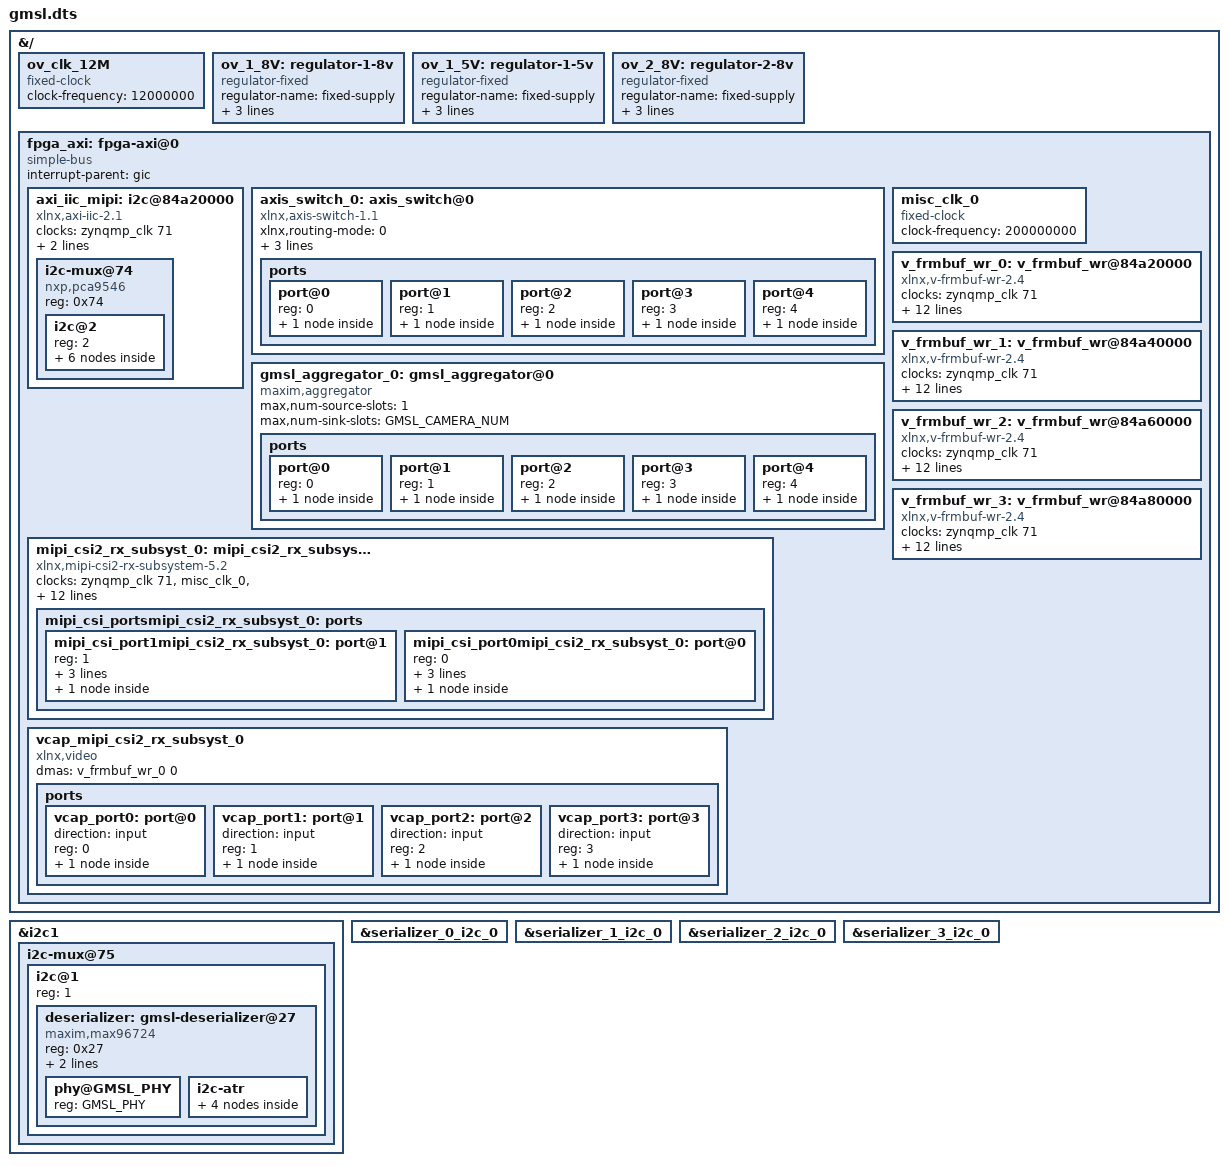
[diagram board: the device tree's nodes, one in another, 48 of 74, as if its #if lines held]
// SPDX-License-Identifier: GPL-2.0
/*
 */

#include <dt-bindings/gpio/gpio.h>

/dts-v1/;
/plugin/;

//#define BRD_KRIA
#define BRD_ZCU

#define GMSL_CAM_ISX021
//#define GMSL_CAM_OVX03A

//GMSL defines
#define GMSL_CAMERA_NUM	1
#define GMSL_PHY	0x1

#if (GMSL_CAMERA_NUM >= 1)
#define GMSL_CAMERA_0
#endif
#if (GMSL_CAMERA_NUM >= 2)
#define GMSL_CAMERA_1
#endif
#if (GMSL_CAMERA_NUM >= 3)
#define GMSL_CAMERA_2
#endif
#if (GMSL_CAMERA_NUM >= 4)
#define GMSL_CAMERA_3
#endif

#define GMSL_SER_0_HEX_ADDR	0x41
#define GMSL_SER_1_HEX_ADDR	0x42
#define GMSL_SER_2_HEX_ADDR	0x43
#define GMSL_SER_3_HEX_ADDR	0x44

#define GMSL_CAM_0_HEX_ADDR	0x1b
#define GMSL_CAM_1_HEX_ADDR	0x1c
#define GMSL_CAM_2_HEX_ADDR	0x1d
#define GMSL_CAM_3_HEX_ADDR	0x1e

#define _CONCAT(a, b) a ## b
#define CONCAT(a, b) _CONCAT(a, b)

#define _STRINGIFY(a) # a
#define STRINGIFY(a) _STRINGIFY(a)

&{/} {
	ov_clk_12M: ov_clk_12M {
		compatible = "fixed-clock";
		#clock-cells = <0>;
		clock-frequency = <12000000>;
	};

	ov_1_8V: regulator-1-8v {
		compatible = "regulator-fixed";
		regulator-name = "fixed-supply";
		regulator-min-microvolt = <1800000>;
		regulator-max-microvolt = <1800000>;
		regulator-always-on;
	};

	ov_1_5V: regulator-1-5v {
		compatible = "regulator-fixed";
		regulator-name = "fixed-supply";
		regulator-min-microvolt = <1500000>;
		regulator-max-microvolt = <1500000>;
		regulator-always-on;
	};

	ov_2_8V: regulator-2-8v {
		compatible = "regulator-fixed";
		regulator-name = "fixed-supply";
		regulator-min-microvolt = <2800000>;
		regulator-max-microvolt = <2800000>;
		regulator-always-on;
	};

	fpga_axi: fpga-axi@0 {
		interrupt-parent = <&gic>;
		#address-cells = <1>;
		#size-cells = <1>;
		compatible = "simple-bus";
		ranges = <0 0 0 0xffffffff>;
#ifdef BRD_KRIA
		axi_iic_mipi: i2c@84a20000 {
			#address-cells = <1>;
			#size-cells = <0>;
			clock-names = "s_axi_aclk";
			clocks = <&zynqmp_clk 71>;
			compatible = "xlnx,axi-iic-2.1", "xlnx,xps-iic-2.00.a";
			reg = <0x84a20000 0x1000>;
			interrupts = <0 108 4>;
		};
#endif

		axis_switch_0: axis_switch@0 {
			compatible = "xlnx,axis-switch-1.1";
			xlnx,routing-mode = <0>;
			xlnx,num-si-slots = <1>;
			xlnx,num-mi-slots = <GMSL_CAMERA_NUM>;
			clock-names = "aclk";
			clocks = <&zynqmp_clk 71>;
			ports {
				#address-cells = <1>;
				#size-cells = <0>;
				port@0 {
					reg = <0>;
					switch_in0: endpoint {
						remote-endpoint = <&mipi_csirx_outmipi_csi2_rx_subsyst_0>;
					};
				};
#if defined (GMSL_CAMERA_0)
				port@1 {
					reg = <1>;
					switch_out0: endpoint {
						remote-endpoint = <&vcap_portswitch0>;
					};
				};
#endif
#if defined (GMSL_CAMERA_1)
				port@2 {
					reg = <2>;
					switch_out1: endpoint {
						remote-endpoint = <&vcap_portswitch1>;
					};
				};
#endif
#if defined (GMSL_CAMERA_2)
				port@3 {
					reg = <3>;
					switch_out2: endpoint {
						remote-endpoint = <&vcap_portswitch2>;
					};
				};
#endif
#if defined (GMSL_CAMERA_3)
				port@4 {
					reg = <4>;
					switch_out3: endpoint {
						remote-endpoint = <&vcap_portswitch3>;
					};
				};
#endif
			};
		};

		gmsl_aggregator_0: gmsl_aggregator@0 {
			compatible = "maxim,aggregator";
			max,num-source-slots = <1>;
			max,num-sink-slots = <GMSL_CAMERA_NUM>;
			ports {
				#address-cells = <1>;
				#size-cells = <0>;
				port@0 {
					reg = <0>;
					aggr_out0: endpoint {
						remote-endpoint = <&mipi_csi_inmipi_csi2_rx_subsyst_0>;
					};
				};
#if defined (GMSL_CAMERA_0)
				port@1 {
					reg = <1>;
					csi_in0: endpoint {
						remote-endpoint = <&deser_out0>;
#ifdef BRD_ZCU
						data-lanes = <1 2 3 4>;
#else
						data-lanes = <1 2>;
#endif
					};
				};
#endif
#if defined (GMSL_CAMERA_1)
				port@2 {
					reg = <2>;
					csi_in1: endpoint {
						remote-endpoint = <&deser_out1>;
#ifdef BRD_ZCU
						data-lanes = <1 2 3 4>;
#else
						data-lanes = <1 2>;
#endif
					};
				};
#endif
#if defined (GMSL_CAMERA_2)
				port@3 {
					reg = <3>;
					csi_in2: endpoint {
						remote-endpoint = <&deser_out2>;
#ifdef BRD_ZCU
						data-lanes = <1 2 3 4>;
#else
						data-lanes = <1 2>;
#endif
					};
				};
#endif
#if defined (GMSL_CAMERA_3)
				port@4 {
					reg = <4>;
					csi_in3: endpoint {
						remote-endpoint = <&deser_out3>;
#ifdef BRD_ZCU
						data-lanes = <1 2 3 4>;
#else
						data-lanes = <1 2>;
#endif
					};
				};
#endif
			};
		};

		mipi_csi2_rx_subsyst_0: mipi_csi2_rx_subsystem@84a00000 {
			clock-names = "lite_aclk", "dphy_clk_200M", "video_aclk";
			clocks = <&zynqmp_clk 71>, <&misc_clk_0>, <&zynqmp_clk 71>;
			compatible = "xlnx,mipi-csi2-rx-subsystem-5.2", "xlnx,mipi-csi2-rx-subsystem-5.0";
			interrupt-names = "csirxss_csi_irq";
			interrupt-parent = <&gic>;
			interrupts = <0 109 4>;
			xlnx,csi-pxl-format = <0x1E>;
#ifdef BRD_ZCU
			video-reset-gpios = <&gpio 99 GPIO_ACTIVE_LOW>;
#else
			video-reset-gpios = <&gpio 79 GPIO_ACTIVE_LOW>;
#endif
			reg = <0x84a00000 0x2000>;
			xlnx,axis-tdata-width = <32>;
			xlnx,dphy-present ;
			xlnx,max-lanes = <4>;
			xlnx,ppc = <2>;
			xlnx,vc = <4>;
			xlnx,vfb ;
			mipi_csi_portsmipi_csi2_rx_subsyst_0: ports {
				#address-cells = <1>;
				#size-cells = <0>;
				mipi_csi_port1mipi_csi2_rx_subsyst_0: port@1 {
					/* Fill cfa-pattern=rggb for raw data types, other fields video-format and video-width user needs to fill */
					reg = <1>;
					xlnx,cfa-pattern = "rggb";
					xlnx,video-format = <0>;
					xlnx,video-width = <8>;
					mipi_csirx_outmipi_csi2_rx_subsyst_0: endpoint {
						remote-endpoint = <&switch_in0>;
					};
				};
				mipi_csi_port0mipi_csi2_rx_subsyst_0: port@0 {
					/* Fill cfa-pattern=rggb for raw data types, other fields video-format,video-width user needs to fill */
					/* User need to add something like remote-endpoint=<&out> under the node csiss_in:endpoint */
					reg = <0>;
					xlnx,cfa-pattern = "rggb";
					xlnx,video-format = <0>;
					xlnx,video-width = <8>;
					mipi_csi_inmipi_csi2_rx_subsyst_0: endpoint {
						remote-endpoint = <&aggr_out0>;
#ifdef BRD_ZCU
						data-lanes = <1 2 3 4>;
#else
						data-lanes = <1 2>;
#endif
					};
				};
			};
		};

		misc_clk_0: misc_clk_0 {
			#clock-cells = <0>;
			clock-frequency = <200000000>;
			compatible = "fixed-clock";
		};

#if defined (GMSL_CAMERA_0)
		v_frmbuf_wr_0: v_frmbuf_wr@84a20000 {
			#dma-cells = <1>;
			clock-names = "ap_clk";
			clocks = <&zynqmp_clk 71>;
			compatible = "xlnx,v-frmbuf-wr-2.4", "xlnx,axi-frmbuf-wr-v2.2";
			interrupt-names = "interrupt";
			interrupt-parent = <&gic>;
			interrupts = <0 107 4>;
#ifdef BRD_ZCU
			reset-gpios = <&gpio 100 GPIO_ACTIVE_LOW>;
#else
			reset-gpios = <&gpio 80 GPIO_ACTIVE_LOW>;
#endif
			reg = <0x84a20000 0x10000>;
			xlnx,dma-addr-width = <32>;
			xlnx,max-height = <2160>;
			xlnx,max-width = <3840>;
			xlnx,pixels-per-clock = <2>;
			xlnx,s-axi-ctrl-addr-width = <0x7>;
			xlnx,s-axi-ctrl-data-width = <0x20>;
			xlnx,vid-formats = "bgr888", "uyvy", "yuyv", "nv16";
			xlnx,video-width = <8>;
		};
#endif
#if defined (GMSL_CAMERA_1)
		v_frmbuf_wr_1: v_frmbuf_wr@84a40000 {
			#dma-cells = <1>;
			clock-names = "ap_clk";
			clocks = <&zynqmp_clk 71>;
			compatible = "xlnx,v-frmbuf-wr-2.4", "xlnx,axi-frmbuf-wr-v2.2";
			interrupt-names = "interrupt";
			interrupt-parent = <&gic>;
			interrupts = <0 106 4>;
#ifdef BRD_ZCU
			reset-gpios = <&gpio 101 GPIO_ACTIVE_LOW>;
#else
			reset-gpios = <&gpio 81 GPIO_ACTIVE_LOW>;
#endif
			reg = <0x84a40000 0x10000>;
			xlnx,dma-addr-width = <32>;
			xlnx,max-height = <2160>;
			xlnx,max-width = <3840>;
			xlnx,pixels-per-clock = <2>;
			xlnx,s-axi-ctrl-addr-width = <0x7>;
			xlnx,s-axi-ctrl-data-width = <0x20>;
			xlnx,vid-formats = "bgr888", "uyvy", "yuyv", "nv16";
			xlnx,video-width = <8>;
		};
#endif
#if defined (GMSL_CAMERA_2)
		v_frmbuf_wr_2: v_frmbuf_wr@84a60000 {
			#dma-cells = <1>;
			clock-names = "ap_clk";
			clocks = <&zynqmp_clk 71>;
			compatible = "xlnx,v-frmbuf-wr-2.4", "xlnx,axi-frmbuf-wr-v2.2";
			interrupt-names = "interrupt";
			interrupt-parent = <&gic>;
			interrupts = <0 105 4>;
#ifdef BRD_ZCU
			reset-gpios = <&gpio 102 GPIO_ACTIVE_LOW>;
#else
			reset-gpios = <&gpio 82 GPIO_ACTIVE_LOW>;
#endif
			reg = <0x84a60000 0x10000>;
			xlnx,dma-addr-width = <32>;
			xlnx,max-height = <2160>;
			xlnx,max-width = <3840>;
			xlnx,pixels-per-clock = <2>;
			xlnx,s-axi-ctrl-addr-width = <0x7>;
			xlnx,s-axi-ctrl-data-width = <0x20>;
			xlnx,vid-formats = "bgr888", "uyvy", "yuyv", "nv16";
			xlnx,video-width = <8>;
		};
#endif
#if defined (GMSL_CAMERA_3)
		v_frmbuf_wr_3: v_frmbuf_wr@84a80000 {
			#dma-cells = <1>;
			clock-names = "ap_clk";
			clocks = <&zynqmp_clk 71>;
			compatible = "xlnx,v-frmbuf-wr-2.4", "xlnx,axi-frmbuf-wr-v2.2";
			interrupt-names = "interrupt";
			interrupt-parent = <&gic>;
			interrupts = <0 104 4>;
#ifdef BRD_ZCU
			reset-gpios = <&gpio 103 GPIO_ACTIVE_LOW>;
#else
			reset-gpios = <&gpio 83 GPIO_ACTIVE_LOW>;
#endif
			reg = <0x84a80000 0x10000>;
			xlnx,dma-addr-width = <32>;
			xlnx,max-height = <2160>;
			xlnx,max-width = <3840>;
			xlnx,pixels-per-clock = <2>;
			xlnx,s-axi-ctrl-addr-width = <0x7>;
			xlnx,s-axi-ctrl-data-width = <0x20>;
			xlnx,vid-formats = "bgr888", "uyvy", "yuyv", "nv16";
			xlnx,video-width = <8>;
		};
#endif
		vcap_mipi_csi2_rx_subsyst_0 {
			compatible = "xlnx,video";
			dma-names = "port0", "port1", "port2", "port3";
#if (GMSL_CAMERA_NUM == 1)
			dmas = <&v_frmbuf_wr_0 0>;
#elif (GMSL_CAMERA_NUM == 2)
			dmas = <&v_frmbuf_wr_0 0>, <&v_frmbuf_wr_1 0>;
#elif (GMSL_CAMERA_NUM == 3)
			dmas = <&v_frmbuf_wr_0 0>, <&v_frmbuf_wr_1 0>, <&v_frmbuf_wr_2 0>;
#elif (GMSL_CAMERA_NUM == 4)
			dmas = <&v_frmbuf_wr_0 0>, <&v_frmbuf_wr_1 0>, <&v_frmbuf_wr_2 0>, <&v_frmbuf_wr_3 0>;
#else
	#error "GMSL_CAMERA_NUM has wrong value"
#endif
			ports {
				#address-cells = <1>;
				#size-cells = <0>;
#if defined (GMSL_CAMERA_0)
				vcap_port0: port@0 {
					direction = "input";
					reg = <0>;
					vcap_portswitch0: endpoint {
						remote-endpoint = <&switch_out0>;
					};
				};
#endif
#if defined (GMSL_CAMERA_1)
				vcap_port1: port@1 {
					direction = "input";
					reg = <1>;
					vcap_portswitch1: endpoint {
						remote-endpoint = <&switch_out1>;
					};
				};
#endif
#if defined (GMSL_CAMERA_2)
				vcap_port2: port@2 {
					direction = "input";
					reg = <2>;
					vcap_portswitch2: endpoint {
						remote-endpoint = <&switch_out2>;
					};
				};
#endif
#if defined (GMSL_CAMERA_3)
				vcap_port3: port@3 {
					direction = "input";
					reg = <3>;
					vcap_portswitch3: endpoint {
						remote-endpoint = <&switch_out3>;
					};
				};
#endif
			};
		};
	};

};

#ifdef BRD_ZCU
&i2c1{
	#address-cells = <1>;
	#size-cells = <0>;
	i2c-mux@75 {
		#address-cells = <1>;
		#size-cells = <0>;
		i2c@1 {
			#address-cells = <1>;
			#size-cells = <0>;
			reg = <1>;
			deserializer: gmsl-deserializer@27 {
				#address-cells = <1>;
				#size-cells = <0>;
				compatible = "maxim,max96724";
				reg = <0x27>;
			};
		};
	};
};
#endif

#ifdef BRD_KRIA
&axi_iic_mipi { 
	i2c-mux@74 {
		compatible = "nxp,pca9546"; /* u18 */
		#address-cells = <1>;
		#size-cells = <0>;
		reg = <0x74>;
		i2c@2 {
			#address-cells = <1>;
			#size-cells = <0>;
			reg = <2>;
			deserializer: gmsl-deserializer@27 {
				#address-cells = <1>;
				#size-cells = <0>;
				compatible = "maxim,max96724";
				reg = <0x27>;

				gpio-controller;
				#gpio-cells = <2>;

				pinctrl-0 = <&mfp0_fsync0 &mfp1_fsync1 &mfp2_fsync2 &mfp3_fsync3>;
				pinctrl-names = "default";
				pins {
					mfp0_fsync0: mfp0_fsync0 {
						pins = "mfp0";
						function = "gpio";
						bias-pull-up;
						input-enable;
						maxim,jitter-compensation = <1>;
						maxim,gmsl-tx-a = <1>;
						maxim,gmsl-tx-id-a = <0>;
						maxim,gmsl-tx-b = <1>;
						maxim,gmsl-tx-id-b = <0>;
						maxim,gmsl-tx-c = <1>;
						maxim,gmsl-tx-id-c = <0>;
						maxim,gmsl-tx-d = <1>;
						maxim,gmsl-tx-id-d = <0>;
					};

					mfp1_fsync1: mfp1_fsync1 {
						pins = "mfp1";
						function = "gpio";
						bias-pull-up;
						input-enable;
						maxim,jitter-compensation = <1>;
						maxim,gmsl-tx-a = <1>;
						maxim,gmsl-tx-id-a = <1>;
						maxim,gmsl-tx-b = <1>;
						maxim,gmsl-tx-id-b = <1>;
						maxim,gmsl-tx-c = <1>;
						maxim,gmsl-tx-id-c = <1>;
						maxim,gmsl-tx-d = <1>;
						maxim,gmsl-tx-id-d = <1>;
					};

					mfp2_fsync2: mfp2_fsync2 {
						pins = "mfp2";
						function = "gpio";
						bias-pull-up;
						input-enable;
						maxim,jitter-compensation = <1>;
						maxim,gmsl-tx-a = <1>;
						maxim,gmsl-tx-id-a = <2>;
						maxim,gmsl-tx-b = <1>;
						maxim,gmsl-tx-id-b = <2>;
						maxim,gmsl-tx-c = <1>;
						maxim,gmsl-tx-id-c = <2>;
						maxim,gmsl-tx-d = <1>;
						maxim,gmsl-tx-id-d = <2>;
					};

					mfp3_fsync3: mfp3_fsync3 {
						pins = "mfp3";
						function = "gpio";
						bias-pull-up;
						input-enable;
						maxim,jitter-compensation = <1>;
						maxim,gmsl-tx-a = <1>;
						maxim,gmsl-tx-id-a = <3>;
						maxim,gmsl-tx-b = <1>;
						maxim,gmsl-tx-id-b = <3>;
						maxim,gmsl-tx-c = <1>;
						maxim,gmsl-tx-id-c = <3>;
						maxim,gmsl-tx-d = <1>;
						maxim,gmsl-tx-id-d = <3>;
					};
				};
			};
		};
	};
};
#endif

&deserializer {
	phy@GMSL_PHY {
		reg = <GMSL_PHY>;
	};


#if defined(GMSL_CAMERA_0)
	#define DESER_CH_INDEX 0
	#include "gmsl-deserializer-channel.dtsi"
#endif

#if defined(GMSL_CAMERA_1)
	#define DESER_CH_INDEX 1
	#include "gmsl-deserializer-channel.dtsi"
#endif

#if defined(GMSL_CAMERA_2)
	#define DESER_CH_INDEX 2
	#include "gmsl-deserializer-channel.dtsi"
#endif

#if defined(GMSL_CAMERA_3)
	#define DESER_CH_INDEX 3
	#include "gmsl-deserializer-channel.dtsi"
#endif
};

&deserializer {
	i2c-alias-pool = <
		GMSL_SER_0_HEX_ADDR
		GMSL_SER_1_HEX_ADDR
		GMSL_SER_2_HEX_ADDR
		GMSL_SER_3_HEX_ADDR
	>;

	i2c-atr {
		#address-cells = <1>;
		#size-cells = <0>;

#if defined(GMSL_CAMERA_0)
		deserializer_i2c_0: i2c@0 {
			#address-cells = <1>;
			#size-cells = <0>;

			reg = <0>;
		};
#endif

#if defined(GMSL_CAMERA_1)
		deserializer_i2c_1: i2c@1 {
			#address-cells = <1>;
			#size-cells = <0>;

			reg = <1>;
		};
#endif

#if defined(GMSL_CAMERA_2)
		deserializer_i2c_2: i2c@2 {
			#address-cells = <1>;
			#size-cells = <0>;

			reg = <2>;
		};
#endif

#if defined(GMSL_CAMERA_3)
		deserializer_i2c_3: i2c@3 {
			#address-cells = <1>;
			#size-cells = <0>;

			reg = <3>;
		};
#endif
	};
};

#if defined(GMSL_CAMERA_0)
serializer_0_i2c_bus: &deserializer_i2c_0 {};
#endif
#if defined(GMSL_CAMERA_1)
serializer_1_i2c_bus: &deserializer_i2c_1 {};
#endif
#if defined(GMSL_CAMERA_2)
serializer_2_i2c_bus: &deserializer_i2c_2 {};
#endif
#if defined(GMSL_CAMERA_3)
serializer_3_i2c_bus: &deserializer_i2c_3 {};
#endif

#if defined(GMSL_CAMERA_0)
&serializer_0_i2c_bus {
	#define SER_INDEX 0
	#define SER_I2C_ADDR_POLL_0 GMSL_CAM_0_HEX_ADDR
#if defined(GMSL_CAM_ISX021)
	#define SER_HEX_REG 0x62
	#define SER_COMPAT "maxim,max9295a"
#endif
	#include "gmsl-serializer.dtsi"
};
#endif

#if defined(GMSL_CAMERA_1)
&serializer_1_i2c_bus {
	#define SER_INDEX 1
	#define SER_I2C_ADDR_POLL_0 GMSL_CAM_1_HEX_ADDR
#if defined(GMSL_CAM_ISX021)
	#define SER_HEX_REG 0x62
	#define SER_COMPAT "maxim,max9295a"
#endif
	#include "gmsl-serializer.dtsi"
};
#endif

#if defined(GMSL_CAMERA_2)
&serializer_2_i2c_bus {
	#define SER_INDEX 2
	#define SER_I2C_ADDR_POLL_0 GMSL_CAM_2_HEX_ADDR
#if defined(GMSL_CAM_ISX021)
	#define SER_HEX_REG 0x62
	#define SER_COMPAT "maxim,max9295a"
#endif
	#include "gmsl-serializer.dtsi"
};
#endif

#if defined(GMSL_CAMERA_3)
&serializer_3_i2c_bus {
	#define SER_INDEX 3
	#define SER_I2C_ADDR_POLL_0 GMSL_CAM_3_HEX_ADDR
#if defined(GMSL_CAM_ISX021)
	#define SER_HEX_REG 0x62
	#define SER_COMPAT "maxim,max9295a"
#endif
	#include "gmsl-serializer.dtsi"
};
#endif

#if defined(GMSL_CAMERA_0)
camera_0_i2c_bus: &serializer_0_i2c_0 {};
#endif
#if defined(GMSL_CAMERA_1)
camera_1_i2c_bus: &serializer_1_i2c_0 {};
#endif
#if defined(GMSL_CAMERA_2)
camera_2_i2c_bus: &serializer_2_i2c_0 {};
#endif
#if defined(GMSL_CAMERA_3)
camera_3_i2c_bus: &serializer_3_i2c_0 {};
#endif

#if defined(GMSL_CAMERA_0)
&camera_0_i2c_bus {
#if defined(GMSL_CAM_OVX03A)
	#define OVX03A_INDEX 0
	#include "gmsl-ovx03a.dtsi"
#endif
#if defined(GMSL_CAM_ISX021)
	#define ISX021_INDEX 0
	#include "gmsl-isx021.dtsi"
#endif
};
#endif

#if defined(GMSL_CAMERA_1)
&camera_1_i2c_bus {
#if defined(GMSL_CAM_OVX03A)
	#define OVX03A_INDEX 1
	#include "gmsl-ovx03a.dtsi"
#endif
#if defined(GMSL_CAM_ISX021)
	#define ISX021_INDEX 1
	#include "gmsl-isx021.dtsi"
#endif
};
#endif

#if defined(GMSL_CAMERA_2)
&camera_2_i2c_bus {
#if defined(GMSL_CAM_OVX03A)
	#define OVX03A_INDEX 2
	#include "gmsl-ovx03a.dtsi"
#endif
#if defined(GMSL_CAM_ISX021)
	#define ISX021_INDEX 2
	#include "gmsl-isx021.dtsi"
#endif
};
#endif

#if defined(GMSL_CAMERA_3)
&camera_3_i2c_bus {
#if defined(GMSL_CAM_OVX03A)
	#define OVX03A_INDEX 3
	#include "gmsl-ovx03a.dtsi"
#endif
#if defined(GMSL_CAM_ISX021)
	#define ISX021_INDEX 3
	#include "gmsl-isx021.dtsi"
#endif
};
#endif
